BO_ 318291879 BSM_STATUS_RIGHT: 8 XXX
 SG_ BSM_ALERT : 4|1@0+ (1,0) [0|1] "" XXX
 SG_ BSM_MODE : 6|2@0+ (1,0) [0|3] "" XXX

BO_ 318291615 BSM_STATUS_LEFT: 8 XXX
 SG_ BSM_ALERT : 4|1@0+ (1,0) [0|1] "" XXX
 SG_ BSM_MODE : 6|2@0+ (1,0) [0|3] "" XXX

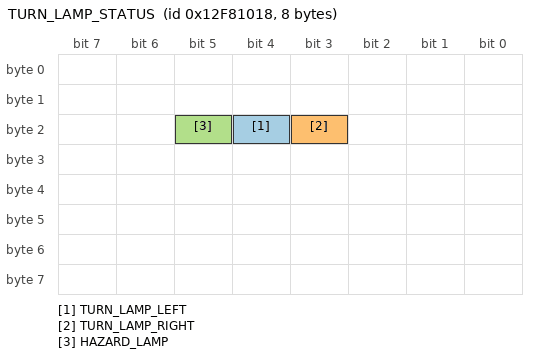
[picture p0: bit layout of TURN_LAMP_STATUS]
BO_ 318246936 TURN_LAMP_STATUS: 8 XXX
 SG_ TURN_LAMP_LEFT : 20|1@0+ (1,0) [0|1] "" XXX
 SG_ TURN_LAMP_RIGHT : 19|1@0+ (1,0) [0|1] "" XXX
 SG_ HAZARD_LAMP : 21|1@0+ (1,0) [0|1] "" XXX

BO_ 384954392 BCM_KWP_RESP: 8 XXX
 SG_ RESP_CODE : 7|8@0+ (1,0) [0|255] "" XXX
 SG_ RESP_DATA : 15|8@0+ (1,0) [0|255] "" XXX

VAL_ 318291879 BSM_MODE 2 "blind_spot" 1 "cross_traffic" 0 "off";
VAL_ 318291615 BSM_MODE 2 "blind_spot" 1 "cross_traffic" 0 "off";
